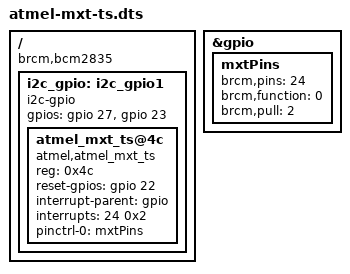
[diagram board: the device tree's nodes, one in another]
// Definitions for BMP085/BMP180 digital barometric pressure and temperature sensors from Bosch Sensortec
/dts-v1/;
/plugin/;

/ {
        compatible = "brcm,bcm2835";
	fragment@0 {
		target-path = "/";
		__overlay__{
			i2c_gpio:i2c_gpio1 {
				compatible = "i2c-gpio";
				gpios = <&gpio 27 0 /* sda */
					 &gpio 23 0 /* scl */
					>;
				//i2c-gpio-delay-us = <2>;        /* ~100 kHz */
				#address-cells = <1>;
				#size-cells = <0>;
			};
		};
	};
        fragment@1 {
                target = <&i2c_gpio>;
                __overlay__ {
                        #address-cells = <1>;
                        #size-cells = <0>;
                        status = "okay";
                        atmel_mxt_ts@4c {
                                compatible = "atmel,atmel_mxt_ts";
                                reg = <0x4c>;
                                reset-gpios = <&gpio 22 0>;
                                interrupt-parent = <&gpio>;
                                interrupts = <24 0x2>; /* Falling edge only */
                                pinctrl-names = "default";
                                pinctrl-0 = <&mxtPins>;
                        };
			
                };
        };

        fragment@2 {
	        target = <&gpio>;
	        __overlay__ {
		        mxtPins: mxtPins {
			        brcm,pins = <24>;
			        brcm,function = <0>; /* in */
			        brcm,pull = <2>; /* up pull */
		        };
	        };
        };
};
